# bb_core_model: IP-XACT component
VLNV IcronTechnologies:IcronTechnologies:bb_core_model:1.0

## Parameters
addr_width = 8
bus_width = 32

## Bus interfaces (logical=physical port)
default_map: slave AGNISYS:AGNISYS:APB:1.0, memory map bb_coremap
  pclk=pclk, presetn=presetn, psel=psel, penable=penable, pwrite=pwrite, pprot=pprot, pstrb=pstrb, pwdata=pwdata, paddr=paddr, pready=pready, prdata=prdata, pslverr=pslverr

## Ports
in pclk
in presetn
in psel
in penable
in pwrite
in pprot[2:0]
in pstrb[(bus_width div 8 )-1:0]
in pwdata[bus_width -1:0]
in paddr[addr_width -1:0]
out pready
out prdata[bus_width -1:0]
out pslverr

## Address spaces and blocks
bb_coremap.bb_core: base 0x000, range 0x100, width 32

## Registers
Registers are 32-bit, read-write, reset 0x0 unless marked. A register's access mark holds for its fields unless they carry their own. Offsets are from the block's base; lines under a group give offsets from that group; [hi:lo] are bit positions; {n}, {i} and the like mark numbered series; 'fields as' and 'values as' point back to an identical list; <NAME> marks a mode.

## bb_coremap.bb_core — BlackBird Core Registers
Base 0x00000000
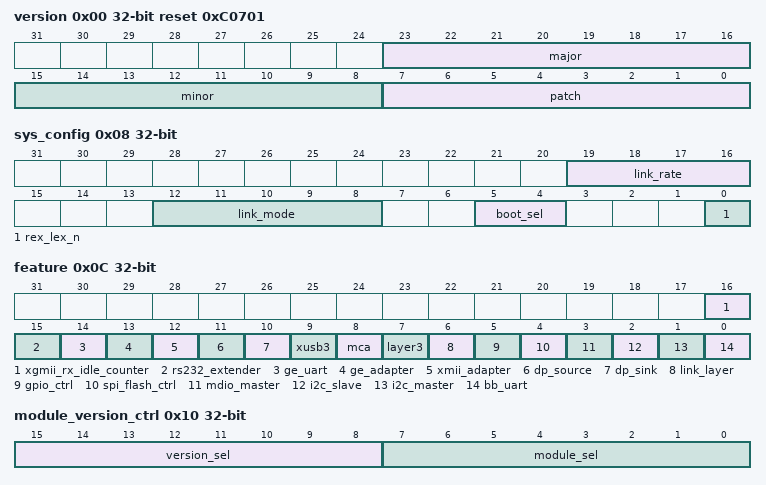
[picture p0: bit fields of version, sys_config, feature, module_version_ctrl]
0x00 version ro reset 0xC0701
  [23:16] major — Major version
  [15:8] minor — Minor version
  [7:0] patch — Patch version
0x04 cpu_freq ro — CPU Frequency
  [31:0] value — CPU frequency in Hz
0x08 sys_config ro — System configuration
  [19:16] link_rate
  [12:8] link_mode
  [5:4] boot_sel — Boot Select 0 : Program Mode 1 : Boot from Flash 2 : Boot from I2C Slave 3 : Boot from IRAM
  [0] rex_lex_n — Extender Select 0 : Local (LEX) 1 : Remote (REX)
0x0C feature ro — Features present
  [16] xgmii_rx_idle_counter — XGMII RX Idle Counter present
  [15] rs232_extender — RS-232 Extender present
  [14] ge_uart — GE UART present
  [13] ge_adapter — GE Adapter present
  [12] xmii_adapter — XMII Adapter present
  [11] dp_source — DisplayPort Source present
  [10] dp_sink — DisplayPort Sink present
  [9] xusb3 — XUSB3 present
  [8] mca — MCA present
  [7] layer3 — Layer 3 present
  [6] link_layer — Data Link Layer present
  [5] gpio_ctrl — GPIO controller present
  [4] spi_flash_ctrl — SPI Flash Controller present
  [3] mdio_master — MDIO Master present
  [2] i2c_slave — I2C Slave present
  [1] i2c_master — I2C Master present
  [0] bb_uart — BB UART present
0x10 module_version_ctrl — Module version control
  [15:8] version_sel — Version select - Use this for modules that have more than one version
  [7:0] module_sel — Module select - To read a version of a particular module, set this field to the index of the module in the feature register - If a module has more than one version, use the version_sel field to select the one of interest - Once the right module is selected and where applicable the right version within the module, issue a read of the module_version register to obtain the version of interest - Note that a module must be present to be able to read its version - Note that some modules do not have a register interface and as a result do not have a version
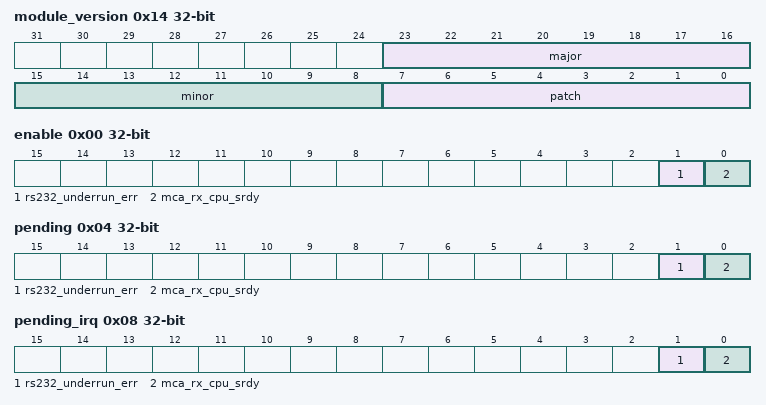
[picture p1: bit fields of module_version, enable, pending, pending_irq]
0x14 module_version ro
  [23:16] major — Module major version
  [15:8] minor — Module minor version
  [7:0] patch — Module patch version
0x18 irq group — BlackBird Core Interrupt register group
  0x00 enable — Interrupt Enable register - Write 1 to enable, 0 to mask an interrupt
    [1] rs232_underrun_err — RS-232 Underrun Error Interrupt
    [0] mca_rx_cpu_srdy — MCA RX CPU SRDY Interrupt
  0x04 pending — Pending register - This indicates which events are pending, Write 1 to clear
    [1] rs232_underrun_err write-1-clears — Edge-triggered - Active-High RS-232 Underrun Error
    [0] mca_rx_cpu_srdy write-1-clears — Level-triggered - Active-High MCA RX CPU SRDY
  0x08 pending_irq ro — Interrupt Pending register - This indicates which pending events are enabled to cause an interrupt
    [1] rs232_underrun_err — Edge-triggered - Active-High RS-232 Underrun Error
    [0] mca_rx_cpu_srdy — Level-triggered - Active-High MCA RX CPU SRDY
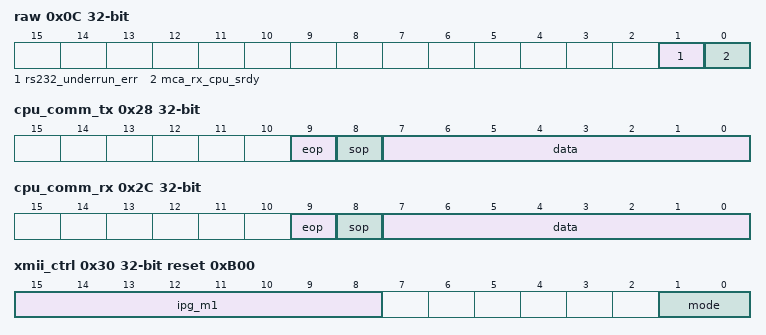
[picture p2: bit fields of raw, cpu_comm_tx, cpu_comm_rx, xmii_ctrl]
  0x0C raw ro — This register contains the registered state of interrupt signals
    [1] rs232_underrun_err — Current state of the RS-232 Underrun Error (Active-High)
    [0] mca_rx_cpu_srdy — Current state of the MCA RX CPU SRDY (Active-High)
0x28 cpu_comm_tx — CPU Communication TX Control
  [9] eop — End-Of-Packet (Active-High) Indicates whether this is the last byte of a packet
  [8] sop — Start-Of-Packet (Active-High) Indicates whether this is the first byte of a packet
  [7:0] data — Byte to write into the communication channel
0x2C cpu_comm_rx ro — CPU Communication RX Status
  [9] eop — End-Of-Packet (Active-High) Indicates whether this is the last byte of a packet
  [8] sop — Start-Of-Packet (Active-High) Indicates whether this is the first byte of a packet
  [7:0] data — Byte read from the communication channel
0x30 xmii_ctrl reset 0xB00 — XMII control
  [15:8] ipg_m1 — Inter Packet Gap - 1 (minimum number of clock cycles between packets, e.g to guarantee 12 set this to 11)
  [1:0] mode — XMII Mode: 0 : GMII 1 : MII 2 : RGMII 3 : RMII
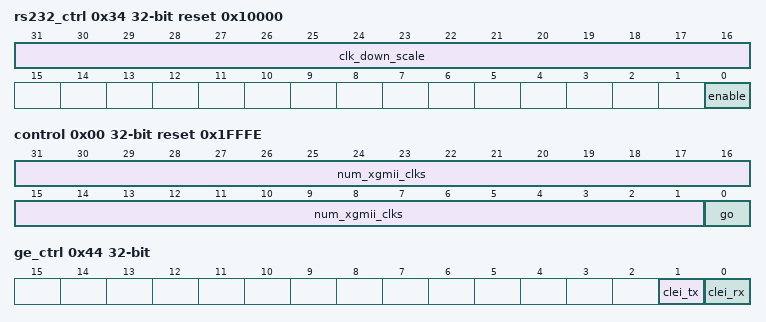
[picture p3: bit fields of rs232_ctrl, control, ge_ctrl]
0x34 rs232_ctrl reset 0x10000 — RS-232 control
  [31:16] clk_down_scale — Module Clock Down Scaling Factor Scale the module clock to a minimum of 16x the baud rate: floor(<freq>/(16x<baud rate>))
  [0] enable — Enable (Active-High)
0x38 xgmii_idle_counter group
  0x00 control reset 0x1FFFE
    [31:1] num_xgmii_clks — Number of XGMII clocks to do the XGMII idle count
    [0] go — Write a 1 to initiate a XGMII idle count. HW will clear this field upon completion. Once cleared the number of idles can be obtained.
  0x04 status ro
    [31:0] idle_count — Number of XGMII idles counted
0x40 ahb_to_apb_ctrl — AHB to APB Bridge control
  [0] timeout_hresp — HRESP on timeout 0 : OKAY 1 : ERROR
0x44 ge_ctrl — GoldenEars control
  [1] clei_tx — 0 : PTP to GMII 1 : PTP to CLEI
  [0] clei_rx — 0 : GMII to PTP 1 : CLEI to PTP (with flow control)
0x48 scratchpad group — Scratchpad Register Group
  {0x0+4j} spr[{j}] (j=0..3) — Scratchpad Register
    [31:0] value
